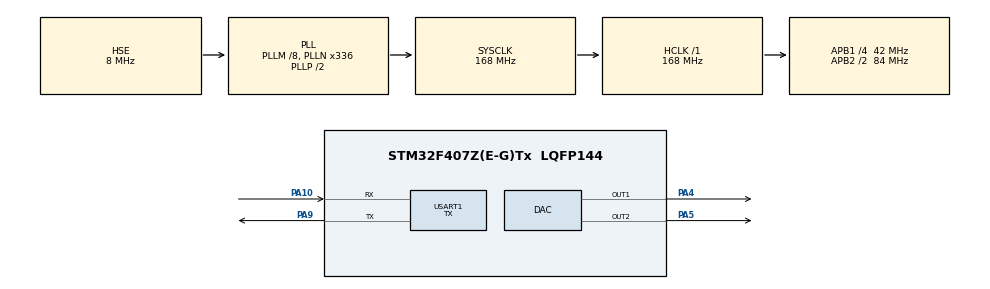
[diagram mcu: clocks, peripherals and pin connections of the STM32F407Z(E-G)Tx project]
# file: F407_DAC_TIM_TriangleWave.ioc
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DAC.DAC_OutputBuffer2=DAC_OUTPUTBUFFER_DISABLE
DAC.DAC_Trigger=DAC_TRIGGER_T2_TRGO
DAC.DAC_Trigger2=DAC_TRIGGER_T2_TRGO
DAC.TriangleAmplitude=DAC_TRIANGLEAMPLITUDE_2047
DAC.TriangleAmplitude2=DAC_TRIANGLEAMPLITUDE_1023
DAC.WaveGeneration=TriangleWaveGeneration
DAC.WaveGeneration2=TriangleWaveGeneration
Mcu.Family=STM32F4
Mcu.Name=STM32F407Z(E-G)Tx
Mcu.Package=LQFP144
NVIC.PriorityGroup=NVIC_PRIORITYGROUP_4
PA10.Mode=Asynchronous
PA10.Signal=USART1_RX
PA13.Mode=Serial_Wire
PA13.Signal=SYS_JTMS-SWDIO
PA14.Mode=Serial_Wire
PA14.Signal=SYS_JTCK-SWCLK
PA4.Signal=COMP_DAC1_group
PA5.Signal=COMP_DAC2_group
PA9.Mode=Asynchronous
PA9.Signal=USART1_TX
PH0-OSC_IN.Mode=HSE-External-Oscillator
PH0-OSC_IN.Signal=RCC_OSC_IN
PH1-OSC_OUT.Mode=HSE-External-Oscillator
PH1-OSC_OUT.Signal=RCC_OSC_OUT
ProjectManager.HeapSize=0x200
ProjectManager.StackSize=0x400
ProjectManager.TargetToolchain=MDK-ARM V5.27
RCC.48MHZClocksFreq_Value=84000000
RCC.AHBFreq_Value=168000000
RCC.APB1CLKDivider=RCC_HCLK_DIV4
RCC.APB1Freq_Value=42000000
RCC.APB1TimFreq_Value=84000000
RCC.APB2CLKDivider=RCC_HCLK_DIV2
RCC.APB2Freq_Value=84000000
RCC.APB2TimFreq_Value=168000000
RCC.CortexFreq_Value=168000000
RCC.HCLKFreq_Value=168000000
RCC.HSE_VALUE=8000000
RCC.HSI_VALUE=16000000
RCC.LSE_VALUE=32768
RCC.PLLM=8
RCC.PLLN=336
RCC.PLLSourceVirtual=RCC_PLLSOURCE_HSE
RCC.SYSCLKFreq_VALUE=168000000
RCC.SYSCLKSource=RCC_SYSCLKSOURCE_PLLCLK
RCC.VCOOutputFreq_Value=336000000
SH.COMP_DAC1_group.0=DAC_OUT1,DAC_OUT1
SH.COMP_DAC2_group.0=DAC_OUT2,DAC_OUT2
TIM2.Period=1
TIM2.Prescaler=41
TIM2.TIM_MasterOutputTrigger=TIM_TRGO_UPDATE
TIM2.TIM_MasterSlaveMode=TIM_MASTERSLAVEMODE_DISABLE
USART1.Mode=MODE_TX
USART1.VirtualMode=VM_ASYNC
VP_TIM2_VS_ClockSourceINT.Mode=Internal
board=custom

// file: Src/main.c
/* USER CODE BEGIN Header */
/**
  ******************************************************************************
  * @file           : main.c
  * @brief          : Main program body
  ******************************************************************************
  * @attention
  *
  * <h2><center>&copy; Copyright (c) 2021 STMicroelectronics.
  * All rights reserved.</center></h2>
  *
  * This software component is licensed by ST under BSD 3-Clause license,
  * the "License"; You may not use this file except in compliance with the
  * License. You may obtain a copy of the License at:
  *                        opensource.org/licenses/BSD-3-Clause
  *
  ******************************************************************************
  */
/* USER CODE END Header */
#include "main.h"
#include "dac.h"
#include "tim.h"
#include "usart.h"
#include "gpio.h"

void SystemClock_Config(void);

int main(void)
{

  /* MCU Configuration--------------------------------------------------------*/

  /* Reset of all peripherals, Initializes the Flash interface and the Systick. */
  HAL_Init();

  /* Configure the system clock */
  SystemClock_Config();

  /* Initialize all configured peripherals */
  MX_GPIO_Init();
  MX_DAC_Init();
  MX_TIM2_Init();
  MX_USART1_UART_Init();
  /* USER CODE BEGIN 2 */

	HAL_TIM_Base_Start(&htim2);			//没使用中断功能
	HAL_DAC_Start(&hdac, DAC_CHANNEL_1);
	HAL_DAC_Start(&hdac, DAC_CHANNEL_2);

  /* USER CODE END 2 */

  /* Infinite loop */
  while (1)
  {

  }
}

void SystemClock_Config(void)
{
  RCC_OscInitTypeDef RCC_OscInitStruct = {0};
  RCC_ClkInitTypeDef RCC_ClkInitStruct = {0};

  /** Configure the main internal regulator output voltage
  */
  __HAL_RCC_PWR_CLK_ENABLE();
  __HAL_PWR_VOLTAGESCALING_CONFIG(PWR_REGULATOR_VOLTAGE_SCALE1);
  /** Initializes the RCC Oscillators according to the specified parameters
  * in the RCC_OscInitTypeDef structure.
  */
  RCC_OscInitStruct.OscillatorType = RCC_OSCILLATORTYPE_HSE;
  RCC_OscInitStruct.HSEState = RCC_HSE_ON;
  RCC_OscInitStruct.PLL.PLLState = RCC_PLL_ON;
  RCC_OscInitStruct.PLL.PLLSource = RCC_PLLSOURCE_HSE;
  RCC_OscInitStruct.PLL.PLLM = 8;
  RCC_OscInitStruct.PLL.PLLN = 336;
  RCC_OscInitStruct.PLL.PLLP = RCC_PLLP_DIV2;
  RCC_OscInitStruct.PLL.PLLQ = 4;
  if (HAL_RCC_OscConfig(&RCC_OscInitStruct) != HAL_OK)
  {
    Error_Handler();
  }
  /** Initializes the CPU, AHB and APB buses clocks
  */
  RCC_ClkInitStruct.ClockType = RCC_CLOCKTYPE_HCLK|RCC_CLOCKTYPE_SYSCLK
                              |RCC_CLOCKTYPE_PCLK1|RCC_CLOCKTYPE_PCLK2;
  RCC_ClkInitStruct.SYSCLKSource = RCC_SYSCLKSOURCE_PLLCLK;
  RCC_ClkInitStruct.AHBCLKDivider = RCC_SYSCLK_DIV1;
  RCC_ClkInitStruct.APB1CLKDivider = RCC_HCLK_DIV4;
  RCC_ClkInitStruct.APB2CLKDivider = RCC_HCLK_DIV2;

  if (HAL_RCC_ClockConfig(&RCC_ClkInitStruct, FLASH_LATENCY_5) != HAL_OK)
  {
    Error_Handler();
  }
}

void Error_Handler(void)
{
  __disable_irq();
  while (1)
  {
  }
}

/************************ (C) COPYRIGHT STMicroelectronics *****END OF FILE****/
